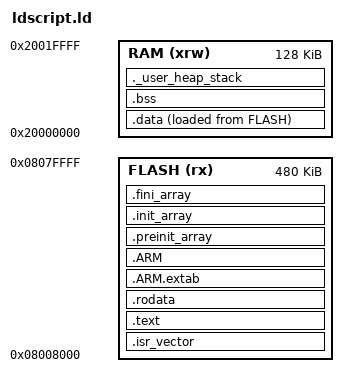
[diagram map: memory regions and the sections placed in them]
/* Octopus F446: 32 KiB BTT loader, contiguous 480 KiB application; no Flash NVM. */
/* Entry Point */
ENTRY(Reset_Handler)

/* Highest address in CCMRAM */


/* Generate a link error if heap and stack don't fit into RAM */
_Min_Heap_Size = 0x200;;      /* required amount of heap  */
_Min_Stack_Size = 0x400;; /* required amount of stack */

/* Specify the memory areas */
MEMORY
{
FLASH (rx)      : ORIGIN = 0x08008000, LENGTH = 512K - 32K
RAM (xrw)      : ORIGIN = 0x20000000, LENGTH = 128K

}

/* Define output sections */
SECTIONS
{
  /* The startup code goes first into FLASH */
  .isr_vector :
  {
    . = ALIGN(4);
    KEEP(*(.isr_vector)) /* Startup code */
    . = ALIGN(4);
  } >FLASH
  /* The program code and other data goes into FLASH */
  .text ALIGN(4):
  {
    . = ALIGN(4);
    __etext_start = .;
    *(.text)           /* .text sections (code) */
    *(.text*)          /* .text* sections (code) */
    *(.glue_7)         /* glue arm to thumb code */
    *(.glue_7t)        /* glue thumb to arm code */
    *(.eh_frame)

    KEEP (*(.init))
    KEEP (*(.fini))

    . = ALIGN(4);
    _etext = .;        /* define a global symbols at end of code */
  } >FLASH

  /* Constant data goes into FLASH */
  .rodata ALIGN(4):
  {
    . = ALIGN(4);
    *(.rodata)         /* .rodata sections (constants, strings, etc.) */
    *(.rodata*)        /* .rodata* sections (constants, strings, etc.) */
    . = ALIGN(4);
  } >FLASH

  .ARM.extab   : { *(.ARM.extab* .gnu.linkonce.armextab.*) } >FLASH
  .ARM : {
    __exidx_start = .;
    *(.ARM.exidx*)
    __exidx_end = .;
  } >FLASH

  .preinit_array     :
  {
    PROVIDE_HIDDEN (__preinit_array_start = .);
    KEEP (*(.preinit_array*))
    PROVIDE_HIDDEN (__preinit_array_end = .);
  } >FLASH
  .init_array :
  {
    PROVIDE_HIDDEN (__init_array_start = .);
    KEEP (*(SORT(.init_array.*)))
    KEEP (*(.init_array*))
    PROVIDE_HIDDEN (__init_array_end = .);
  } >FLASH
  .fini_array :
  {
    PROVIDE_HIDDEN (__fini_array_start = .);
    KEEP (*(SORT(.fini_array.*)))
    KEEP (*(.fini_array*))
    PROVIDE_HIDDEN (__fini_array_end = .);
  } >FLASH

  /* used by the startup to initialize data */
  _sidata = LOADADDR(.data);

  /* Initialized data sections goes into RAM, load LMA copy after code */
  .data :
  {
    . = ALIGN(4);
    _sdata = .;        /* create a global symbol at data start */
    *(.data)           /* .data sections */
    *(.data*)          /* .data* sections */

    . = ALIGN(4);
    _edata = .;        /* define a global symbol at data end */
  } >RAM AT> FLASH
  _firmware_end = _sidata + (_edata - _sdata);

  /* Uninitialized data section */
  . = ALIGN(4);
  .bss (NOLOAD) :
  {
    /* This is used by the startup in order to initialize the .bss secion */
    _sbss = .;         /* define a global symbol at bss start */
    __bss_start__ = _sbss;
    _sccmram = .;
    *(.ccmram .ccmram*)
    _eccmram = .;
    *(.bss)
    *(.bss*)
    *(COMMON)

    . = ALIGN(4);
    _ebss = .;         /* define a global symbol at bss end */
    __bss_end__ = _ebss;
  } >RAM

  /* User_heap_stack section, used to check that there is enough RAM left */
  ._user_heap_stack :
  {
    . = ALIGN(4);
    PROVIDE ( end = . );
    PROVIDE ( _end = . );
    . = . + _Min_Heap_Size;
    . = . + _Min_Stack_Size;
    . = ALIGN(4);
  } >RAM

  /* Remove information from the standard libraries */
  /DISCARD/ :
  {
    libc.a ( * )
    libm.a ( * )
    libgcc.a ( * )
  }

  .ARM.attributes 0 : { *(.ARM.attributes) }

  /* Provide system stack location, some bootloaders do not like a stack right at end of RAM */
  PROVIDE(_estack = ORIGIN(RAM) + LENGTH(RAM) - 4);
  PROVIDE(_firmware_crc = _firmware_end);
  PROVIDE(_ccmramend = _eccmram); /* no separate CCM heap on F446 */
  __rrf_mcu_id = 0x446;
  ASSERT(_firmware_end <= 0x08080000, "F446 Flash overflow")
  ASSERT(_end + _Min_Heap_Size + _Min_Stack_Size <= _estack, "F446 SRAM overflow")

}
